# ADuCM4050 register map
Vendor: Analog Devices; Series: ADuCM4050; File version: 1p0
CPU: CM4 r0p1, little endian, MPU, FPU, 3 interrupt priority bits
Registers are 32-bit, read-write, reset 0x0 unless marked. A register's access mark holds for its fields unless they carry their own. Offsets are from the block's base; [hi:lo] are bit positions; {n}, {i} and the like mark numbered series.

## NVIC0 — Cortex Interrupt Controller
Base 0xE000E000
0x04 INTNUM — Interrupt Control Type
  [31:0] VALUE range 0x00000000..0xFFFFFFFF
0x10 STKSTA — Systick Control and Status
  [31:0] VALUE range 0x00000000..0xFFFFFFFF
0x14 STKLD — Systick Reload Value
  [31:0] VALUE range 0x00000000..0xFFFFFFFF
0x18 STKVAL — Systick Current Value
  [31:0] VALUE range 0x00000000..0xFFFFFFFF
0x1C STKCAL — Systick Calibration Value
  [31:0] VALUE range 0x00000000..0xFFFFFFFF
0x100 INTSETE0 — IRQ0..31 Set_Enable
  [31:0] VALUE range 0x00000000..0xFFFFFFFF
0x104 INTSETE1 — IRQ32..63 Set_Enable
  [31:0] VALUE range 0x00000000..0xFFFFFFFF
0x108 INTSETE2 — IRQ64..95 Set_Enable
  [31:0] VALUE range 0x00000000..0xFFFFFFFF
0x180 INTCLRE0 — IRQ0..31 Clear_Enable
  [31:0] VALUE range 0x00000000..0xFFFFFFFF
0x184 INTCLRE1 — IRQ32..63 Clear_Enable
  [31:0] VALUE range 0x00000000..0xFFFFFFFF
0x188 INTCLRE2 — IRQ64..95 Clear_Enable
  [31:0] VALUE range 0x00000000..0xFFFFFFFF
0x200 INTSETP0 — IRQ0..31 Set_Pending
  [31:0] VALUE range 0x00000000..0xFFFFFFFF
0x204 INTSETP1 — IRQ32..63 Set_Pending
  [31:0] VALUE range 0x00000000..0xFFFFFFFF
0x208 INTSETP2 — IRQ64..95 Set_Pending
  [31:0] VALUE range 0x00000000..0xFFFFFFFF
0x280 INTCLRP0 — IRQ0..31 Clear_Pending
  [31:0] VALUE range 0x00000000..0xFFFFFFFF
0x284 INTCLRP1 — IRQ32..63 Clear_Pending
  [31:0] VALUE range 0x00000000..0xFFFFFFFF
0x288 INTCLRP2 — IRQ64..95 Clear_Pending
  [31:0] VALUE range 0x00000000..0xFFFFFFFF
0x300 INTACT0 — IRQ0..31 Active Bit
  [31:0] VALUE range 0x00000000..0xFFFFFFFF
0x304 INTACT1 — IRQ32..63 Active Bit
  [31:0] VALUE range 0x00000000..0xFFFFFFFF
0x308 INTACT2 — IRQ64..95 Active Bit
  [31:0] VALUE range 0x00000000..0xFFFFFFFF
0x400 INTPRI0 — IRQ0..3 Priority
  [31:0] VALUE range 0x00000000..0xFFFFFFFF
0x404 INTPRI1 — IRQ4..7 Priority
  [31:0] VALUE range 0x00000000..0xFFFFFFFF
0x408 INTPRI2 — IRQ8..11 Priority
  [31:0] VALUE range 0x00000000..0xFFFFFFFF
0x40C INTPRI3 — IRQ12..15 Priority
  [31:0] VALUE range 0x00000000..0xFFFFFFFF
0x410 INTPRI4 — IRQ16..19 Priority
  [31:0] VALUE range 0x00000000..0xFFFFFFFF
0x414 INTPRI5 — IRQ20..23 Priority
  [31:0] VALUE range 0x00000000..0xFFFFFFFF
0x418 INTPRI6 — IRQ24..27 Priority
  [31:0] VALUE range 0x00000000..0xFFFFFFFF
0x41C INTPRI7 — IRQ28..31 Priority
  [31:0] VALUE range 0x00000000..0xFFFFFFFF
0x420 INTPRI8 — IRQ32..35 Priority
  [31:0] VALUE range 0x00000000..0xFFFFFFFF
0x424 INTPRI9 — IRQ36..39 Priority
  [31:0] VALUE range 0x00000000..0xFFFFFFFF
0x428 INTPRI10 — IRQ40..43 Priority
  [31:0] VALUE range 0x00000000..0xFFFFFFFF
0x42C INTPRI11 — IRQ44..47 Priority
  [31:0] VALUE range 0x00000000..0xFFFFFFFF
0x430 INTPRI12 — IRQ48..51 Priority
  [31:0] VALUE range 0x00000000..0xFFFFFFFF
0x434 INTPRI13 — IRQ52..55 Priority
  [31:0] VALUE range 0x00000000..0xFFFFFFFF
0x438 INTPRI14 — IRQ56..59 Priority
  [31:0] VALUE range 0x00000000..0xFFFFFFFF
0x43C INTPRI15 — IRQ60..63 Priority
  [31:0] VALUE range 0x00000000..0xFFFFFFFF
0x440 INTPRI16 — IRQ64..67 Priority
  [31:0] VALUE range 0x00000000..0xFFFFFFFF
0x444 INTPRI17 — IRQ68..71 Priority
  [31:0] VALUE range 0x00000000..0xFFFFFFFF
0xD00 INTCPID — CPUID Base
  [31:0] VALUE range 0x00000000..0xFFFFFFFF
0xD04 INTSTA — Interrupt Control State
  [31:0] VALUE range 0x00000000..0xFFFFFFFF
0xD08 INTVEC — Vector Table Offset
  [31:0] VALUE range 0x00000000..0xFFFFFFFF
0xD0C INTAIRC — Application Interrupt/Reset Control
  [31:0] VALUE range 0x00000000..0xFFFFFFFF
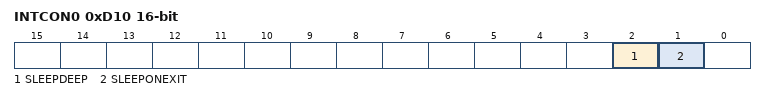
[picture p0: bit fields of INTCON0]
0xD10 INTCON0 16-bit — System Control
  [2] SLEEPDEEP — Deep Sleep Flag for Hibernate Mode
    0=NO_SLEEPDEEP (Sleep Deep is not enabled); 1=SLEEPDEEP (Sleep Deep is enabled)
  [1] SLEEPONEXIT — Sleeps the Core on Exit from an ISR
    0=NO_SLEEPONEXIT (Sleep On Exit is not enabled); 1=SLEEPONEXIT (Sleep On Exit is enabled)
0xD14 INTCON1 — Configuration Control
  [31:0] VALUE range 0x00000000..0xFFFFFFFF
0xD18 INTSHPRIO0 — System Handlers 4-7 Priority
  [31:0] VALUE range 0x00000000..0xFFFFFFFF
0xD1C INTSHPRIO1 — System Handlers 8-11 Priority
  [31:0] VALUE range 0x00000000..0xFFFFFFFF
0xD20 INTSHPRIO3 — System Handlers 12-15 Priority
  [31:0] VALUE range 0x00000000..0xFFFFFFFF
0xD24 INTSHCSR — System Handler Control and State
  [31:0] VALUE range 0x00000000..0xFFFFFFFF
0xD28 INTCFSR — Configurable Fault Status
  [31:0] VALUE range 0x00000000..0xFFFFFFFF
0xD2C INTHFSR — Hard Fault Status
  [31:0] VALUE range 0x00000000..0xFFFFFFFF
0xD30 INTDFSR — Debug Fault Status
  [31:0] VALUE range 0x00000000..0xFFFFFFFF
0xD34 INTMMAR — Mem Manage Address
  [31:0] VALUE range 0x00000000..0xFFFFFFFF
0xD38 INTBFAR — Bus Fault Address
  [31:0] VALUE range 0x00000000..0xFFFFFFFF
0xD3C INTAFSR — Auxiliary Fault Status
  [31:0] VALUE range 0x00000000..0xFFFFFFFF
0xD40 INTPFR0 — Processor Feature Register 0
  [31:0] VALUE range 0x00000000..0xFFFFFFFF
0xD44 INTPFR1 — Processor Feature Register 1
  [31:0] VALUE range 0x00000000..0xFFFFFFFF
0xD48 INTDFR0 — Debug Feature Register 0
  [31:0] VALUE range 0x00000000..0xFFFFFFFF
0xD4C INTAFR0 — Auxiliary Feature Register 0
  [31:0] VALUE range 0x00000000..0xFFFFFFFF
{0xD50+4i} INTMMFR{i} (i=0..3) — Memory Model Feature Register {i}
  [31:0] VALUE range 0x00000000..0xFFFFFFFF
{0xD60+4i} INTISAR{i} (i=0..4) — ISA Feature Register {i}
  [31:0] VALUE range 0x00000000..0xFFFFFFFF
0xF00 INTTRGI — Software Trigger Interrupt Register
  [31:0] VALUE range 0x00000000..0xFFFFFFFF
{0xFC0+4i} INTPID{i} (i=4..7) — Peripheral Identification Register {i}
  [31:0] VALUE range 0x00000000..0xFFFFFFFF
0xFE0 INTPID0 — Peripheral Identification Bits7:0
  [31:0] VALUE range 0x00000000..0xFFFFFFFF
0xFE4 INTPID1 — Peripheral Identification Bits15:8
  [31:0] VALUE range 0x00000000..0xFFFFFFFF
0xFE8 INTPID2 — Peripheral Identification Bits16:23
  [31:0] VALUE range 0x00000000..0xFFFFFFFF
0xFEC INTPID3 — Peripheral Identification Bits24:31
  [31:0] VALUE range 0x00000000..0xFFFFFFFF
0xFF0 INTCID0 — Component Identification Bits7:0
  [31:0] VALUE range 0x00000000..0xFFFFFFFF
0xFF4 INTCID1 — Component Identification Bits15:8
  [31:0] VALUE range 0x00000000..0xFFFFFFFF
0xFF8 INTCID2 — Component Identification Bits16:23
  [31:0] VALUE range 0x00000000..0xFFFFFFFF
0xFFC INTCID3 — Component Identification Bits24:31
  [31:0] VALUE range 0x00000000..0xFFFFFFFF
